# ESP32-C61 register map
Vendor: ESPRESSIF SYSTEMS (SHANGHAI) CO., LTD.; Series: ESP32 C-Series; File version: 1
CPU: RV32IMAC r0p0, little endian, no MPU, no FPU, 0 interrupt priority bits
Address unit: 32 bits
Registers are 32-bit, read-write, reset 0x0 unless marked. A register's access mark holds for its fields unless they carry their own. Offsets are from the block's base; [hi:lo] are bit positions; {n}, {i} and the like mark numbered series.

## GPIO — General Purpose Input/Output
Base 0x60091000
0x00 STRAP ro — pad strapping register
  [15:0] STRAPPING
0x04 OUT — GPIO output register for GPIO0-31
  [31:0] DATA_ORIG
0x08 OUT_W1TS wo — GPIO output set register for GPIO0-31
0x0C OUT_W1TC wo — GPIO output clear register for GPIO0-31
0x10 OUT1 — GPIO output register for GPIO32-33
  [1:0] DATA_ORIG
0x14 OUT1_W1TS wo — GPIO output set register for GPIO32-33
  [1:0] OUT1_W1TS
0x18 OUT1_W1TC wo — GPIO output clear register for GPIO32-33
  [1:0] OUT1_W1TC
0x34 ENABLE — GPIO output enable register for GPIO0-31
  [31:0] DATA
0x38 ENABLE_W1TS wo — GPIO output enable set register for GPIO0-31
0x3C ENABLE_W1TC wo — GPIO output enable clear register for GPIO0-31
0x40 ENABLE1 — GPIO output enable register for GPIO32-33
  [1:0] DATA
0x44 ENABLE1_W1TS wo — GPIO output enable set register for GPIO32-33
  [1:0] ENABLE1_W1TS
0x48 ENABLE1_W1TC wo — GPIO output enable clear register for GPIO32-33
  [1:0] ENABLE1_W1TC
0x64 IN ro — GPIO input register for GPIO0-31
  [31:0] DATA_NEXT
0x68 IN1 ro — GPIO input register for GPIO32-33
  [1:0] DATA_NEXT
0x74 STATUS — GPIO interrupt status register for GPIO0-31
  [31:0] INTERRUPT
0x78 STATUS_W1TS wo — GPIO interrupt status set register for GPIO0-31
0x7C STATUS_W1TC wo — GPIO interrupt status clear register for GPIO0-31
0x80 STATUS1 — GPIO interrupt status register for GPIO32-33
  [1:0] INTERRUPT
0x84 STATUS1_W1TS wo — GPIO interrupt status set register for GPIO32-33
  [1:0] STATUS1_W1TS
0x88 STATUS1_W1TC wo — GPIO interrupt status clear register for GPIO32-33
  [1:0] STATUS1_W1TC
0xA4 PROCPU_INT ro — GPIO_PROCPU_INT interrupt status register for GPIO0-31
0xA8 SDIO_INT ro — GPIO_SDIO_INT interrupt status register for GPIO0-31
0xAC PROCPU_INT1 ro — GPIO_PROCPU_INT interrupt status register for GPIO32-33
  [1:0] PROCPU_INT1
0xB0 SDIO_INT1 ro — GPIO_SDIO_INT interrupt status register for GPIO32-33
  [1:0] SDIO_INT1
0xC4 STATUS_NEXT ro — GPIO interrupt source register for GPIO0-31
  [31:0] STATUS_INTERRUPT_NEXT
0xC8 STATUS_NEXT1 ro — GPIO interrupt source register for GPIO32-33
  [1:0] STATUS_INTERRUPT_NEXT1
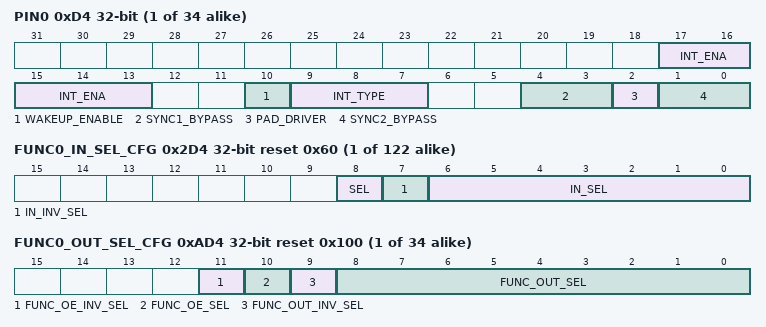
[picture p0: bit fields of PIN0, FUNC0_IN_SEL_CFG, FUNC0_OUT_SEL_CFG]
{0xD4+4i} PIN{i} (i=0..33) — GPIO pin configuration register
  [17:13] INT_ENA — set bit 13 to enable gpio_procpu_int. set bit 15 to enable gpio_sdio_int.
  [10] WAKEUP_ENABLE — set this bit to enable GPIO wakeup.(can only wakeup CPU from Light-sleep Mode)
  [9:7] INT_TYPE — set this value to choose interrupt mode. 0:disable GPIO interrupt. 1:trigger at posedge. 2:trigger at negedge. 3:trigger at any edge. 4:valid at low level. 5:valid at high level
  [4:3] SYNC1_BYPASS — set GPIO input_sync1 signal mode. 0:disable. 1:trigger at negedge. 2or3:trigger at posedge.
  [2] PAD_DRIVER — set this bit to select pad driver. 1:open-drain. 0:normal.
  [1:0] SYNC2_BYPASS — set GPIO input_sync2 signal mode. 0:disable. 1:trigger at negedge. 2or3:trigger at posedge.
{0x2D4+4i} FUNC{i}_IN_SEL_CFG (i=0..121) reset 0x60 — GPIO input function configuration register
  [8] SEL — set this bit to bypass GPIO. 1:do not bypass GPIO. 0:bypass GPIO.
  [7] IN_INV_SEL — set this bit to invert input signal. 1:invert. 0:not invert.
  [6:0] IN_SEL — set this value: s=0-33: connect GPIO[s] to this port. s=0x40: set this port always high level. s=0x60: set this port always low level.
{0xAD4+4i} FUNC{i}_OUT_SEL_CFG (i=0..33) reset 0x100 — GPIO output function select register
  [11] FUNC_OE_INV_SEL — set this bit to invert output enable signal.1:invert.0:not invert.
  [10] FUNC_OE_SEL — set this bit to select output enable signal.1:use GPIO_ENABLE_REG[n] as output enable signal.0:use peripheral output enable signal.
  [9] FUNC_OUT_INV_SEL — set this bit to invert output signal.1:invert.0:not invert.
  [8:0] FUNC_OUT_SEL — The value of the bits: 0<=s<=256. Set the value to select output signal. s=0-127: output of GPIO[n] equals input of peripheral[s]. s=128: output of GPIO[n] equals GPIO_OUT_REG[n].
0xDF8 CLOCK_GATE reset 0x1 — GPIO clock gate register
  [0] CLK_EN — set this bit to enable GPIO clock gate
0xDFC DATE reset 0x2412290 — GPIO version register
  [27:0] DATE — version register
